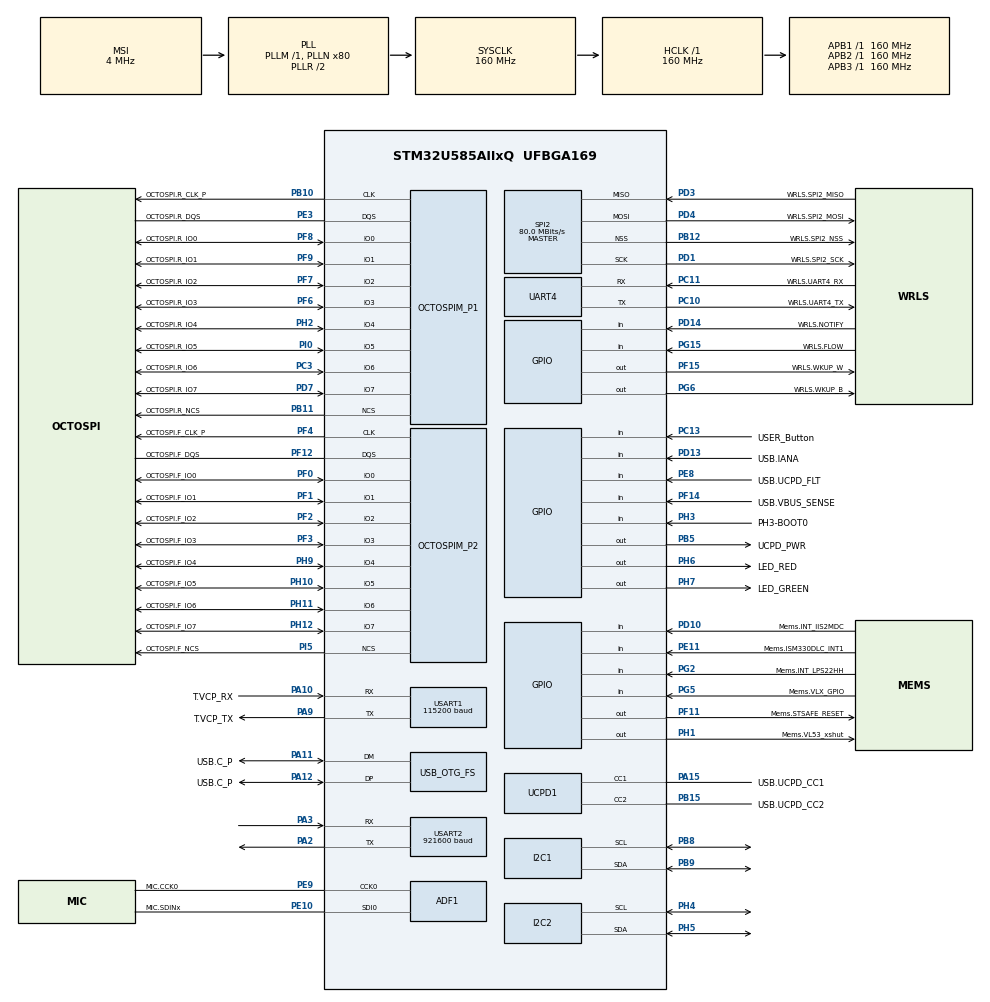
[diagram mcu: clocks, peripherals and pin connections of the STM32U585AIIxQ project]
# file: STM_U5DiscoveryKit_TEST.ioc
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CORTEX_M33_NS.userName=CORTEX_M33
I2C1.Timing=0x30909DEC
I2C2.Timing=0x30909DEC
Mcu.Family=STM32U5
Mcu.Name=STM32U585AIIxQ
Mcu.Package=UFBGA169
NVIC.PriorityGroup=NVIC_PRIORITYGROUP_4
OCTOSPI1.ChipSelectBoundary=10
OCTOSPI1.ClockPrescaler=2
OCTOSPI1.DelayBlockBypass=HAL_OSPI_DELAY_BLOCK_USED
OCTOSPI1.DelayHoldQuarterCycle=HAL_OSPI_DHQC_ENABLE
OCTOSPI1.DeviceSize=23
OCTOSPI1.MemoryType=HAL_OSPI_MEMTYPE_APMEMORY
OCTOSPI1.Refresh=100
OCTOSPI2.ChipSelectBoundary=0
OCTOSPI2.ChipSelectHighTime=2
OCTOSPI2.ClockPrescaler=4
OCTOSPI2.DelayBlockBypass=HAL_OSPI_DELAY_BLOCK_USED
OCTOSPI2.DelayHoldQuarterCycle=HAL_OSPI_DHQC_ENABLE
OCTOSPI2.DeviceSize=26
OCTOSPI2.FifoThreshold=4
OCTOSPI2.MemoryType=HAL_OSPI_MEMTYPE_MACRONIX
PA10.GPIO_Label=T.VCP_RX
PA10.Mode=Asynchronous
PA10.Signal=USART1_RX
PA11.GPIO_Label=USB.C_P
PA11.Mode=Device_Only
PA11.Signal=USB_OTG_FS_DM
PA12.GPIO_Label=USB.C_P
PA12.Mode=Device_Only
PA12.Signal=USB_OTG_FS_DP
PA13\ (JTMS/SWDIO).GPIO_Label=T.SWDIO
PA13\ (JTMS/SWDIO).Mode=Trace_Asynchronous_SW
PA13\ (JTMS/SWDIO).Signal=DEBUG_JTMS-SWDIO
PA14\ (JTCK/SWCLK).GPIO_Label=T.SWCLK
PA14\ (JTCK/SWCLK).Mode=Trace_Asynchronous_SW
PA14\ (JTCK/SWCLK).Signal=DEBUG_JTCK-SWCLK
PA15\ (JTDI).GPIO_Label=USB.UCPD_CC1
PA15\ (JTDI).Mode=Dual_Role_AllSignals
PA15\ (JTDI).Signal=UCPD1_CC1
PA2.Mode=Asynchronous
PA2.Signal=USART2_TX
PA3.Mode=Asynchronous
PA3.Signal=USART2_RX
PA9.GPIO_Label=T.VCP_TX
PA9.Mode=Asynchronous
PA9.Signal=USART1_TX
PB1.GPIO_Label=MIC.SDIN0
PB1.Signal=MDF1_SDI0
PB10.GPIO_Label=OCTOSPI.R_CLK_P
PB10.Mode=O1_P1_CLK
PB10.Signal=OCTOSPIM_P1_CLK
PB11.GPIO_Label=OCTOSPI.R_NCS
PB11.Mode=OCTOSPI1_Port1_NCS
PB11.Signal=OCTOSPIM_P1_NCS
PB12.GPIO_Label=WRLS.SPI2_NSS
PB12.Mode=NSS_Signal_Hard_Output
PB12.Signal=SPI2_NSS
PB15.GPIO_Label=USB.UCPD_CC2
PB15.Mode=Dual_Role_AllSignals
PB15.Signal=UCPD1_CC2
PB3\ (JTDO/TRACESWO).GPIO_Label=T.SWO
PB3\ (JTDO/TRACESWO).Mode=Trace_Asynchronous_SW
PB3\ (JTDO/TRACESWO).Signal=DEBUG_JTDO-SWO
PB5.GPIO_Label=UCPD_PWR
PB5.Signal=GPIO_Output
PB8.Mode=I2C
PB8.Signal=I2C1_SCL
PB9.Mode=I2C
PB9.Signal=I2C1_SDA
PC10.GPIO_Label=WRLS.UART4_TX
PC10.Mode=Asynchronous
PC10.Signal=UART4_TX
PC11.GPIO_Label=WRLS.UART4_RX
PC11.Mode=Asynchronous
PC11.Signal=UART4_RX
PC13.GPIO_Label=USER_Button
PC13.Signal=GPIO_Input
PC14-OSC32_IN\ (PC14).GPIO_Label=PC14-OSC32_IN
PC14-OSC32_IN\ (PC14).Mode=LSE-External-Oscillator
PC14-OSC32_IN\ (PC14).Signal=RCC_OSC32_IN
PC15-OSC32_OUT\ (PC15).GPIO_Label=PC15-OSC32_OUT
PC15-OSC32_OUT\ (PC15).Mode=LSE-External-Oscillator
PC15-OSC32_OUT\ (PC15).Signal=RCC_OSC32_OUT
PC3.GPIO_Label=OCTOSPI.R_IO6
PC3.Mode=OCTOSPI1_IOH_Port1H
PC3.Signal=OCTOSPIM_P1_IO6
PD1.GPIO_Label=WRLS.SPI2_SCK
PD1.Mode=Full_Duplex_Master
PD1.Signal=SPI2_SCK
PD10.GPIO_Label=Mems.INT_IIS2MDC
PD10.Signal=GPIO_Input
PD13.GPIO_Label=USB.IANA
PD13.Signal=GPIO_Input
PD14.GPIO_Label=WRLS.NOTIFY
PD14.Signal=GPIO_Input
PD3.GPIO_Label=WRLS.SPI2_MISO
PD3.Mode=Full_Duplex_Master
PD3.Signal=SPI2_MISO
PD4.GPIO_Label=WRLS.SPI2_MOSI
PD4.Mode=Full_Duplex_Master
PD4.Signal=SPI2_MOSI
PD7.GPIO_Label=OCTOSPI.R_IO7
PD7.Mode=OCTOSPI1_IOH_Port1H
PD7.Signal=OCTOSPIM_P1_IO7
PE10.GPIO_Label=MIC.SDINx
PE10.Mode=MOD_ADF_CCK
PE10.Signal=ADF1_SDI0
PE11.GPIO_Label=Mems.ISM330DLC_INT1
PE11.Signal=GPIO_Input
PE3.GPIO_Label=OCTOSPI.R_DQS
PE3.Mode=OCTOSPI1_Port1_DQS
PE3.Signal=OCTOSPIM_P1_DQS
PE8.GPIO_Label=USB.UCPD_FLT
PE8.Signal=GPIO_Input
PE9.GPIO_Label=MIC.CCK0
PE9.Mode=MOD_MDF_CCK0
PE9.Signal=ADF1_CCK0
PF0.GPIO_Label=OCTOSPI.F_IO0
PF0.Mode=OCTOSPI2_IOL_Port2L
PF0.Signal=OCTOSPIM_P2_IO0
PF1.GPIO_Label=OCTOSPI.F_IO1
PF1.Mode=OCTOSPI2_IOL_Port2L
PF1.Signal=OCTOSPIM_P2_IO1
PF10.GPIO_Label=MIC.CCK1
PF10.Signal=MDF1_CCK1
PF11.GPIO_Label=Mems.STSAFE_RESET
PF11.Signal=GPIO_Output
PF12.GPIO_Label=OCTOSPI.F_DQS
PF12.Mode=OCTOSPI2_Port2_DQS
PF12.Signal=OCTOSPIM_P2_DQS
PF14.GPIO_Label=USB.VBUS_SENSE
PF14.Signal=GPIO_Input
PF15.GPIO_Label=WRLS.WKUP_W
PF15.Signal=GPIO_Output
PF2.GPIO_Label=OCTOSPI.F_IO2
PF2.Mode=OCTOSPI2_IOL_Port2L
PF2.Signal=OCTOSPIM_P2_IO2
PF3.GPIO_Label=OCTOSPI.F_IO3
PF3.Mode=OCTOSPI2_IOL_Port2L
PF3.Signal=OCTOSPIM_P2_IO3
PF4.GPIO_Label=OCTOSPI.F_CLK_P
PF4.Mode=O2_P2_CLK
PF4.Signal=OCTOSPIM_P2_CLK
PF6.GPIO_Label=OCTOSPI.R_IO3
PF6.Mode=OCTOSPI1_IOL_Port1L
PF6.Signal=OCTOSPIM_P1_IO3
PF7.GPIO_Label=OCTOSPI.R_IO2
PF7.Mode=OCTOSPI1_IOL_Port1L
PF7.Signal=OCTOSPIM_P1_IO2
PF8.GPIO_Label=OCTOSPI.R_IO0
PF8.Mode=OCTOSPI1_IOL_Port1L
PF8.Signal=OCTOSPIM_P1_IO0
PF9.GPIO_Label=OCTOSPI.R_IO1
PF9.Mode=OCTOSPI1_IOL_Port1L
PF9.Signal=OCTOSPIM_P1_IO1
PG15.GPIO_Label=WRLS.FLOW
PG15.Signal=GPIO_Input
PG2.GPIO_Label=Mems.INT_LPS22HH
PG2.Signal=GPIO_Input
PG5.GPIO_Label=Mems.VLX_GPIO
PG5.Signal=GPIO_Input
PG6.GPIO_Label=WRLS.WKUP_B
PG6.Signal=GPIO_Output
PH1-OSC_OUT\ (PH1).GPIO_Label=Mems.VL53_xshut
PH1-OSC_OUT\ (PH1).Signal=GPIO_Output
PH10.GPIO_Label=OCTOSPI.F_IO5
PH10.Mode=OCTOSPI2_IOH_Port2H
PH10.Signal=OCTOSPIM_P2_IO5
PH11.GPIO_Label=OCTOSPI.F_IO6
PH11.Mode=OCTOSPI2_IOH_Port2H
PH11.Signal=OCTOSPIM_P2_IO6
PH12.GPIO_Label=OCTOSPI.F_IO7
PH12.Mode=OCTOSPI2_IOH_Port2H
PH12.Signal=OCTOSPIM_P2_IO7
PH2.GPIO_Label=OCTOSPI.R_IO4
PH2.Mode=OCTOSPI1_IOH_Port1H
PH2.Signal=OCTOSPIM_P1_IO4
PH3-BOOT0.GPIO_Label=PH3-BOOT0
PH3-BOOT0.Signal=GPIO_Input
PH4.Mode=I2C
PH4.Signal=I2C2_SCL
PH5.Mode=I2C
PH5.Signal=I2C2_SDA
PH6.GPIO_Label=LED_RED
PH6.Signal=GPIO_Output
PH7.GPIO_Label=LED_GREEN
PH7.Signal=GPIO_Output
PH9.GPIO_Label=OCTOSPI.F_IO4
PH9.Mode=OCTOSPI2_IOH_Port2H
PH9.Signal=OCTOSPIM_P2_IO4
PI0.GPIO_Label=OCTOSPI.R_IO5
PI0.Mode=OCTOSPI1_IOH_Port1H
PI0.Signal=OCTOSPIM_P1_IO5
PI5.GPIO_Label=OCTOSPI.F_NCS
PI5.Mode=OCTOSPI2_Port2_NCS
PI5.Signal=OCTOSPIM_P2_NCS
PWR.PowerMode=PWR_SMPS_SUPPLY
ProjectManager.HeapSize=0x1000
ProjectManager.StackSize=0x400
ProjectManager.TargetToolchain=STM32CubeIDE
RCC.ADCFreq_Value=16000000
RCC.AHBFreq_Value=160000000
RCC.APB1Freq_Value=160000000
RCC.APB1TimFreq_Value=160000000
RCC.APB2Freq_Value=160000000
RCC.APB2TimFreq_Value=160000000
RCC.APB3Freq_Value=160000000
RCC.CortexFreq_Value=160000000
RCC.DACCLockSelectionVirtual=RCC_DAC1CLKSOURCE_LSI
RCC.EPOD_VALUE=4000000
RCC.HCLKFreq_Value=160000000
RCC.HSE_VALUE=16000000
RCC.HSI48_VALUE=48000000
RCC.HSI_VALUE=16000000
RCC.LSIDIV_VALUE=32000
RCC.MSI_VALUE=4000000
RCC.PLLN=80
RCC.SYSCLKFreq_VALUE=160000000
RCC.SYSCLKSource=RCC_SYSCLKSOURCE_PLLCLK
RCC.USBFreq_Value=48000000
RCC.VCOOutputFreq_Value=320000000
SPI2.CalculateBaudRate=80.0 MBits/s
SPI2.Direction=SPI_DIRECTION_2LINES
SPI2.Mode=SPI_MODE_MASTER
SPI2.VirtualNSS=VM_NSSHARD
SPI2.VirtualType=VM_MASTER
USART1.BaudRate=115200
USART1.VirtualMode-Asynchronous=VM_ASYNC
USART2.BaudRate=921600
USART2.VirtualMode-Asynchronous=VM_ASYNC
USB_OTG_FS.VirtualMode=Device_Only
VP_ICACHE_VS_ICACHE.Mode=DirectMappedCache
VP_LPBAMQUEUE_VS_QUEUE.Mode=QUEUEMODE
VP_LPBAM_VS_SIG1.Mode=SmartRun
VP_LPBAM_VS_SIG4.Mode=LPDMA1
VP_MEMORYMAP_VS_MEMORYMAP.Mode=CurAppReg
VP_OCTOSPI1_VS_octo.Mode=octo_mode
VP_OCTOSPI2_VS_octo.Mode=octo_mode
VP_PWR_VS_DBSignals.Mode=DisableDeadBatterySignals
VP_PWR_VS_LPOM.Mode=PowerOptimisation
VP_PWR_VS_SECSignals.Mode=Security/Privilege
board=B-U585I-IOT02A

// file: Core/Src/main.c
/* USER CODE BEGIN Header */
/**
  ******************************************************************************
  * @file           : main.c
  * @brief          : Main program body
  ******************************************************************************
  * @attention
  *
  * Copyright (c) 2026 STMicroelectronics.
  * All rights reserved.
  *
  * This software is licensed under terms that can be found in the LICENSE file
  * in the root directory of this software component.
  * If no LICENSE file comes with this software, it is provided AS-IS.
  *
  ******************************************************************************
  */
/* USER CODE END Header */
#include "main.h"
#include "mdf.h"
#include "i2c.h"
#include "icache.h"
#include "octospi.h"
#include "spi.h"
#include "usart.h"
#include "ucpd.h"
#include "usb_otg.h"
#include "gpio.h"

/* USER CODE BEGIN Includes */
#include "app_inference.h"
#include <stdio.h>
#include "tensorflow/lite/micro/cortex_m_generic/debug_log_callback.h"
/* USER CODE END Includes */

void SystemClock_Config(void);
static void SystemPower_Config(void);

/* USER CODE BEGIN 0 */
/* Printf is now retargeted through semihosting (the debugger itself
   intercepts printf calls) instead of going out over a UART pin.
   This frees the board's single physical UART entirely for the
   binary data protocol used by MATLAB. See project build settings:
   linker must use --specs=rdimon.specs instead of --specs=nosys.specs,
   and initialise_monitor_handles() must run before the first printf. */
extern void initialise_monitor_handles(void);
/* USER CODE END 0 */

int main(void)
{

  /* USER CODE BEGIN 1 */
  initialise_monitor_handles();   // must run before any printf - enables semihosting
  /* USER CODE END 1 */

  /* MCU Configuration--------------------------------------------------------*/

  /* Reset of all peripherals, Initializes the Flash interface and the Systick. */
  HAL_Init();

  /* Configure the System Power */
  SystemPower_Config();

  /* Configure the system clock */
  SystemClock_Config();

  /* Initialize all configured peripherals */
  MX_GPIO_Init();
  MX_ADF1_Init();
  MX_I2C1_Init();
  MX_I2C2_Init();
  MX_ICACHE_Init();
  MX_OCTOSPI1_Init();
  MX_OCTOSPI2_Init();
  MX_SPI2_Init();
  MX_USART1_UART_Init();
  MX_USART2_UART_Init();
  MX_UCPD1_Init();
  MX_USB_OTG_FS_PCD_Init();
  MX_UART4_Init();
  /* USER CODE BEGIN 2 */
  HAL_Delay(1000);
  printf("\r\n=== STM32U585 IoT Discovery SOH Inference ===\r\n");

  RegisterDebugLogCallback(debug_log_printf);   // <-- add this line here

  if (App_Inference_Init() != 0) {
      printf("Init failed - entering error blink loop.\r\n");
      while (1) {
    	  HAL_GPIO_TogglePin(LED_GREEN_GPIO_Port, LED_GREEN_Pin);  // active-low: toggling still works fine
          HAL_Delay(1000);
      }
  }

  printf("Ready. Waiting for windows on USART1 (115200 baud)...\r\n");
  /* USER CODE END 2 */

  /* Infinite loop */
  /* USER CODE BEGIN WHILE */
  while (1)
  {
    App_Inference_RunOnce();
    /* USER CODE END WHILE */

  }
}

void SystemClock_Config(void)
{
  RCC_OscInitTypeDef RCC_OscInitStruct = {0};
  RCC_ClkInitTypeDef RCC_ClkInitStruct = {0};

  /** Configure the main internal regulator output voltage
  */
  if (HAL_PWREx_ControlVoltageScaling(PWR_REGULATOR_VOLTAGE_SCALE1) != HAL_OK)
  {
    Error_Handler();
  }

  /** Initializes the CPU, AHB and APB buses clocks
  */
  RCC_OscInitStruct.OscillatorType = RCC_OSCILLATORTYPE_HSI48|RCC_OSCILLATORTYPE_HSI
                              |RCC_OSCILLATORTYPE_MSI;
  RCC_OscInitStruct.HSIState = RCC_HSI_ON;
  RCC_OscInitStruct.HSI48State = RCC_HSI48_ON;
  RCC_OscInitStruct.HSICalibrationValue = RCC_HSICALIBRATION_DEFAULT;
  RCC_OscInitStruct.MSIState = RCC_MSI_ON;
  RCC_OscInitStruct.MSICalibrationValue = RCC_MSICALIBRATION_DEFAULT;
  RCC_OscInitStruct.MSIClockRange = RCC_MSIRANGE_4;
  RCC_OscInitStruct.PLL.PLLState = RCC_PLL_ON;
  RCC_OscInitStruct.PLL.PLLSource = RCC_PLLSOURCE_MSI;
  RCC_OscInitStruct.PLL.PLLMBOOST = RCC_PLLMBOOST_DIV1;
  RCC_OscInitStruct.PLL.PLLM = 1;
  RCC_OscInitStruct.PLL.PLLN = 80;
  RCC_OscInitStruct.PLL.PLLP = 2;
  RCC_OscInitStruct.PLL.PLLQ = 2;
  RCC_OscInitStruct.PLL.PLLR = 2;
  RCC_OscInitStruct.PLL.PLLRGE = RCC_PLLVCIRANGE_0;
  RCC_OscInitStruct.PLL.PLLFRACN = 0;
  if (HAL_RCC_OscConfig(&RCC_OscInitStruct) != HAL_OK)
  {
    Error_Handler();
  }

  /** Initializes the CPU, AHB and APB buses clocks
  */
  RCC_ClkInitStruct.ClockType = RCC_CLOCKTYPE_HCLK|RCC_CLOCKTYPE_SYSCLK
                              |RCC_CLOCKTYPE_PCLK1|RCC_CLOCKTYPE_PCLK2
                              |RCC_CLOCKTYPE_PCLK3;
  RCC_ClkInitStruct.SYSCLKSource = RCC_SYSCLKSOURCE_PLLCLK;
  RCC_ClkInitStruct.AHBCLKDivider = RCC_SYSCLK_DIV1;
  RCC_ClkInitStruct.APB1CLKDivider = RCC_HCLK_DIV1;
  RCC_ClkInitStruct.APB2CLKDivider = RCC_HCLK_DIV1;
  RCC_ClkInitStruct.APB3CLKDivider = RCC_HCLK_DIV1;

  if (HAL_RCC_ClockConfig(&RCC_ClkInitStruct, FLASH_LATENCY_4) != HAL_OK)
  {
    Error_Handler();
  }
}

/**
  * @brief Power Configuration
  * @retval None
  */
static void SystemPower_Config(void)
{
  HAL_PWREx_EnableVddIO2();

  /*
   * Switch to SMPS regulator instead of LDO
   */
  if (HAL_PWREx_ConfigSupply(PWR_SMPS_SUPPLY) != HAL_OK)
  {
    Error_Handler();
  }
}

void Error_Handler(void)
{
  __disable_irq();
  while (1)
  {
  }
}
